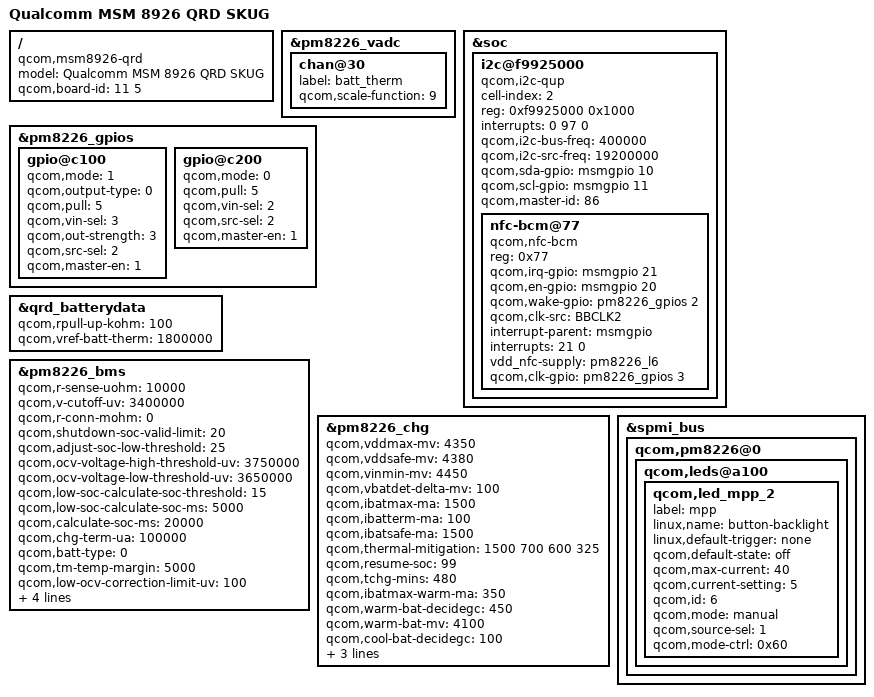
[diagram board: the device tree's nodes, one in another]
/* Copyright (c) 2013-2014, The Linux Foundation. All rights reserved.
 *
 * This program is free software; you can redistribute it and/or modify
 * it under the terms of the GNU General Public License version 2 and
 * only version 2 as published by the Free Software Foundation.
 *
 * This program is distributed in the hope that it will be useful,
 * but WITHOUT ANY WARRANTY; without even the implied warranty of
 * MERCHANTABILITY or FITNESS FOR A PARTICULAR PURPOSE.  See the
 * GNU General Public License for more details.
 */

/dts-v1/;
/include/ "msm8926-v2.dtsi"
/include/ "msm8926-qrd-skug.dtsi"

/ {
	model = "Qualcomm MSM 8926 QRD SKUG";
	compatible = "qcom,msm8926-qrd", "qcom,msm8926", "qcom,qrd";
	qcom,board-id = <11 5>;
};
/*xiangdong add for k-touch therm config*/
&pm8226_vadc {
	chan@30 {
		label = "batt_therm";
		qcom,scale-function = <9>;
	};
};
/*xiangdong add for nfc begin*/
&soc {
	i2c@f9925000 { /* BLSP1 QUP3 */
		cell-index = <2>;
		compatible = "qcom,i2c-qup";
		reg = <0xf9925000 0x1000>;
		#address-cells = <1>;
		#size-cells = <0>;
		reg-names = "qup_phys_addr";
		interrupts = <0 97 0>;
		interrupt-names = "qup_err_intr";
		qcom,i2c-bus-freq = <400000>;
		qcom,i2c-src-freq = <19200000>;
		qcom,sda-gpio = <&msmgpio 10 0>;
		qcom,scl-gpio = <&msmgpio 11 0>;
		qcom,master-id = <86>;

		nfc-bcm@77 {
			compatible = "qcom,nfc-bcm";
			reg = <0x77>;
			qcom,irq-gpio = <&msmgpio 21 0x00>;
			qcom,en-gpio = <&msmgpio 20 0x00>;
			qcom,wake-gpio = <&pm8226_gpios 2 0>;
			qcom,clk-src = "BBCLK2";
			interrupt-parent = <&msmgpio>;
			interrupts = <21 0>;
			vdd_nfc-supply = <&pm8226_l6>;
			qcom,clk-gpio = <&pm8226_gpios 3 0>;
		};
	};
};
&pm8226_gpios {
	gpio@c100 { /* GPIO 2 */
		qcom,mode = <1>;		/* Digital output */
		qcom,output-type = <0>;		/* CMOS logic */
		qcom,pull = <5>;		/* QPNP_PIN_PULL_NO*/
		qcom,vin-sel = <3>;		/* QPNP_PIN_VIN3 */
		qcom,out-strength = <3>;	/* QPNP_PIN_OUT_STRENGTH_HIGH */
		qcom,src-sel = <2>;		/* QPNP_PIN_SEL_FUNC_1 */
		qcom,master-en = <1>;		/* Enable GPIO */
	};

	gpio@c200 { /* GPIO 3 */
		qcom,mode = <0>;		/* QPNP_PIN_MODE_DIG_IN */
		qcom,pull = <5>;		/* QPNP_PIN_PULL_NO */
		qcom,vin-sel = <2>;		/* QPNP_PIN_VIN2 */
		qcom,src-sel = <2>;		/* QPNP_PIN_SEL_FUNC_1 */
		qcom,master-en = <1>;
	};
};
/*xiangdong add for nfc end*/
/*xiangdong add for battery begin*/
&qrd_batterydata {
	qcom,rpull-up-kohm = <100>;
	qcom,vref-batt-therm = <1800000>;

	/include/ "TY_batterydata-qrd-4v35-1850mah.dtsi"
};

&pm8226_bms {
	qcom,r-sense-uohm = <10000>;
	qcom,v-cutoff-uv = <3400000>;
	qcom,r-conn-mohm = <0>;
	qcom,shutdown-soc-valid-limit = <20>;
	qcom,adjust-soc-low-threshold = <25>;
	qcom,ocv-voltage-high-threshold-uv = <3750000>;
	qcom,ocv-voltage-low-threshold-uv = <3650000>;
	qcom,low-soc-calculate-soc-threshold = <15>;
	qcom,low-soc-calculate-soc-ms = <5000>;
	qcom,calculate-soc-ms = <20000>;
	qcom,chg-term-ua = <100000>;
	qcom,batt-type = <0>;
	qcom,tm-temp-margin = <5000>;
	qcom,low-ocv-correction-limit-uv = <100>;
	qcom,high-ocv-correction-limit-uv = <50>;
	qcom,hold-soc-est = <3>;
	qcom,low-voltage-threshold = <3420000>;
	qcom,battery-data = <&qrd_batterydata>;
};

&pm8226_chg {
	qcom,vddmax-mv = <4350>;
	qcom,vddsafe-mv = <4380>;
	qcom,vinmin-mv = <4450>;
	qcom,vbatdet-delta-mv = <100>;
	qcom,ibatmax-ma = <1500>;
	qcom,ibatterm-ma = <100>;
	qcom,ibatsafe-ma = <1500>;
	qcom,thermal-mitigation = <1500 700 600 325>;
	qcom,resume-soc = <99>;
	qcom,tchg-mins = <480>;
	qcom,ibatmax-warm-ma = <350>;
	qcom,warm-bat-decidegc = <450>;
	qcom,warm-bat-mv = <4100>;
	qcom,cool-bat-decidegc = <100>;
	qcom,cool-bat-mv = <4100>;
	qcom,ibatmax-cool-ma = <350>;
	qcom,battery-data = <&qrd_batterydata>;
};
/*xiangdong add for battery end*/
/*TYRD wuxh add for key-backlight begin*/
&spmi_bus {
	qcom,pm8226@0 {
		qcom,leds@a100 {
			status = "okay";
			qcom,led_mpp_2 {
				label = "mpp";
				linux,name = "button-backlight";
				linux,default-trigger = "none";
				qcom,default-state = "off";
				qcom,max-current = <40>;
				qcom,current-setting = <5>;
				qcom,id = <6>;
				qcom,mode = "manual";
				qcom,source-sel = <1>;
				qcom,mode-ctrl = <0x60>;
				};
			};
		};
};
